# PY32F002Bxx register map
Vendor: Puya; Series: PY32F0; File version: 1.0.0
Arm 32-bit Cortex-M0+ Microcontroller based device, CPU clock up to 48 MHz.
CPU: CM0+ r0p1, little endian, no MPU, no FPU, 4 interrupt priority bits
Registers are 32-bit, read-write, reset 0x0 unless marked. A register's access mark holds for its fields unless they carry their own. Offsets are from the block's base; lines under a group give offsets from that group; [hi:lo] are bit positions; {n}, {i} and the like mark numbered series; 'fields as' and 'values as' point back to an identical list; <NAME> marks a mode.

## Memory map
0x40002000 TIM14 size 0x400 — General purpose timer
0x40003000 IWDG size 0x400 — Independent watchdog
0x40005400 I2C size 0x400 — Inter integrated circuit
0x40007000 PWR size 0x400 — Power control
0x40007C00 LPTIM1 size 0x400 — Low power timer
0x40010000 SYSCFG size 0x30 — System configuration controller
0x40010200 COMP1 size 0x10 — Comparator 1
0x40010210 COMP2 size 0x10 — Comparator2
0x40012400 ADC size 0x400 — Analog to Digital Converter
0x40012C00 TIM1 size 0x400 — Advanced timer
0x40013000 SPI1 size 0x400 — Serial peripheral interface
0x40013800 USART1 size 0x400 — Universal synchronous asynchronous receiver transmitter
0x40015800 DBG size 0x400 — Debug support
0x40021000 RCC size 0x400 — Reset and clock control
0x40021800 EXTI size 0x400 — External interrupt/event controller
0x40022000 FLASH size 0x400
0x40023000 CRC size 0x400 — CRC calculation unit
0x50000000 GPIOA size 0x400 — General-purpose I/Os
0x50000400 GPIOB size 0x400
0x50000800 GPIOC size 0x400 — General-purpose I/Os

## Interrupts
3 FLASH — FLASH global Interrupt
4 RCC — RCC global Interrupt
5 EXTI0_1 (EXTI) — EXTI Line 0 and 1 Interrupt
6 EXTI2_3 (EXTI) — EXTI Line 2 and 3 Interrupt
7 EXTI4_15 (EXTI) — EXTI Line 4 to 15 Interrupt
12 ADC_COMP (ADC, COMP1, COMP2) — ADC and COMP Interrupts
13 TIM1_BRK_UP_TRG_COM (TIM1) — TIM1 Break, Update, Trigger and Commutation Interrupt
14 TIM1_CC (TIM1) — TIM1 Capture Compare Interrupt
17 LPTIM1_DAC (LPTIM1) — LPTIM1, DAC global Interrupts
19 TIM14 — TIM14 global Interrupt
23 I2C1 (I2C) — I2C1 global Interrupt
25 SPI1 — SPI1 global Interrupt
27 USART1 — USART1 global Interrupt

## COMP1 — Comparator 1
Base 0x40010200
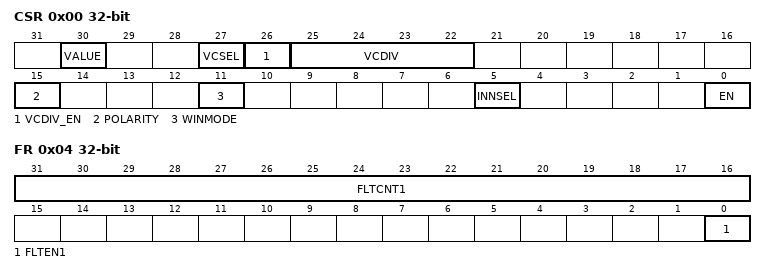
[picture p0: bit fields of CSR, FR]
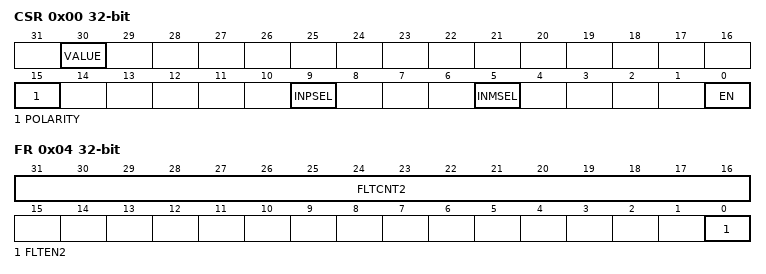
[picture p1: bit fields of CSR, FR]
0x00 CSR — COMP control and status register
  [30] VALUE — Comparator output status
    on read: 0=Low (Comparator output is low); 1=High (Comparator output is high)
  [27] VCSEL
  [26] VCDIV_EN
  [25:22] VCDIV
  [15] POLARITY — Comparator polarity selector
    0=NotInverted (Output is not inverted); 1=Inverted (Output is inverted)
  [11] WINMODE — Comparator non-inverting input selector for window mode
    0=Disabled (COMP1 non-inverting input is connected to COMP1_INP); 1=Enabled (COMP1 non-inverting input is connected to COMP2_INP)
  [5] INNSEL
    0=PB0 (PB0 connected to inverting input); 1=PB1 (PB1 connected to inverting input)
  [0] EN — COMP enable bit
    0=Disabled (Comparator 1 disabled); 1=Enabled (Comparator 1 enabled)
0x04 FR — Comparator Filter register
  [31:16] FLTCNT1 — Comparator filter and counter
  [0] FLTEN1 — Filter enable bit

## COMP2 — Comparator2
Base 0x40010210
0x00 CSR — COMP control and status register
  [30] VALUE — Comparator output status
    on read: 0=Low (Comparator output is low); 1=High (Comparator output is high)
  [15] POLARITY — Comparator polarity selector
    0=NotInverted (Output is not inverted); 1=Inverted (Output is inverted)
  [9] INPSEL — Comparator signal selector for non-inverting input
    0=PA3 (PA3 connected to non-inverting input); 1=VRefCmp (VRef comp)
  [5] INMSEL — Comparator signal selector for inverting input INM
    0=PA4 (PA4 connected to inverting input); 1=PA3 (PA3 connected to inverting input)
  [0] EN — COMP enable bit
    0=Disabled (Comparator 1 disabled); 1=Enabled (Comparator 1 enabled)
0x04 FR — Comparator Filter register
  [31:16] FLTCNT2 — Comparator filter and counter
  [0] FLTEN2 — Filter enable bit
